# System_Mailbox_L4_CFGInterconnect register map
Vendor: Texas Instruments
Peripheral module from a debugger description file (folder omap4430).
Registers are 32-bit, read-write, reset 0x0 unless marked. A register's access mark holds for its fields unless they carry their own. Offsets are as the file gives them; lines under a group give offsets from that group; [hi:lo] are bit positions; {n}, {i} and the like mark numbered series; 'fields as' and 'values as' point back to an identical list; <NAME> marks a mode.

## System_Mailbox_L4_CFGInterconnect
0x00 MAILBOX_REVISION ro reset not defined — This register contains the IP revision code
  [31:0] REVISION — IP Revision
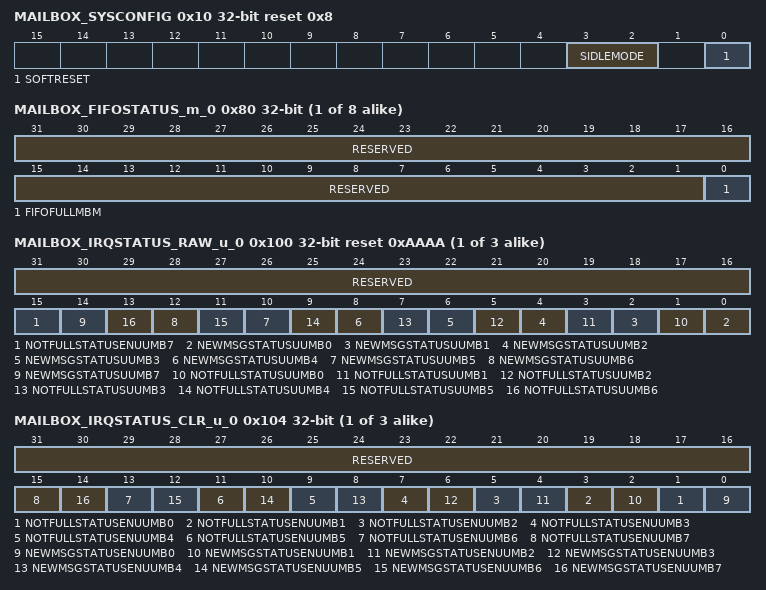
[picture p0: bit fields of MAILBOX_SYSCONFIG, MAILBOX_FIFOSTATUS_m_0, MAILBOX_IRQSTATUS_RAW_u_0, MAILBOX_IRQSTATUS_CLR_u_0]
0x10 MAILBOX_SYSCONFIG reset 0x8 — This register controls the various parameters of the communication interface
  [3:2] SIDLEMODE — Idle Mode
    0=Force-idle. An idle request is acknowledged unconditionally; 1=No-idle. An idle request is never acknowledged; 2=Smart-idle. Acknowledgement to an idle request is given based on the internal activity of the module based on the internal activity of the module; 3=reserved do not use
  [0] SOFTRESET
    0=SOFTRESET_0_r (Soft/Hard reset done); 0=SOFTRESET_0_w (No action); 1=SOFTRESET_1_r (Reset is ongoing); 1=SOFTRESET_1_w (Start the soft reset sequence)
{0x40+4i} MAILBOX_MESSAGE_m_{i} (i=0..7) — The message register stores the next to be read message of the mailbox. Reads remove the message from the FIFO queue.
  [31:0] MESSAGEVALUEMBM — Message in Mailbox
{0x80+4i} MAILBOX_FIFOSTATUS_m_{i} ro (i=0..7) — The FIFO status register has the status related to the mailbox internal FIFO
  [31:1] RESERVED — Reads returns 0
  [0] FIFOFULLMBM — Full flag for Mailbox
    0=FIFOFULLMBM_0_r (Mailbox FIFO is not full); 1=FIFOFULLMBM_1_r (Mailbox FIFO is full)
{0xC0+4i} MAILBOX_MSGSTATUS_m_{i} ro (i=0..7) — The message status register has the status of the messages in the mailbox.
  [2:0] NBOFMSGMBM — Number of unread messages in MailboxNote: Limited to four messages per mailbox.
{0x100+0x10*i} MAILBOX_IRQSTATUS_RAW_u_{i} reset 0xAAAA (i=0..2) — The interrupt status register has the raw status for each event that may be responsible for the generation of an interrupt to the corresponding user - write 1 to a given bit sets this bit. This register is mainly used for debug purpose.
  [31:16] RESERVED — Write 0's for future compatibility. Read returns 0.
  [15] NOTFULLSTATUSENUUMB7 — NotFull Status bit for User u, Mailbox 7
    0=NOTFULLSTATUSENUUMB7_0_r (No event pending (message queue full)); 0=NOTFULLSTATUSENUUMB7_0_w (No action); 1=NOTFULLSTATUSENUUMB7_1_r (Event pending (message queue not full)); 1=NOTFULLSTATUSENUUMB7_1_w (Set the event (for debug))
  [2n] NEWMSGSTATUSUUMB{n} (n=0..7) — NewMessage Status bit for User u, Mailbox {n}
    0=NEWMSGSTATUSUUMB{n}_0_r (No event (message) pending); 0=NEWMSGSTATUSUUMB{n}_0_w (No action); 1=NEWMSGSTATUSUUMB{n}_1_r (Event (message) pending); 1=NEWMSGSTATUSUUMB{n}_1_w (Set the event (for debug))
  [2n+1] NOTFULLSTATUSUUMB{n} (n=0..6) — NotFull Status bit for User u, Mailbox {n}
    0=NOTFULLSTATUSUUMB{n}_0_r (No event pending (message queue full)); 0=NOTFULLSTATUSUUMB{n}_0_w (No action); 1=NOTFULLSTATUSUUMB{n}_1_r (Event pending (message queue not full)); 1=NOTFULLSTATUSUUMB{n}_1_w (Set the event (for debug))
{0x104+0x10*i} MAILBOX_IRQSTATUS_CLR_u_{i} (i=0..2) — The interrupt status register has the status combined with irq-enable for each event that may be responsible for the generation of an interrupt to the corresponding user - write 1 to a given bit resets this bit
  [31:16] RESERVED — Write 0's for future compatibility. Read returns 0.
  [2n+1] NOTFULLSTATUSENUUMB{n} (n=0..7) — NotFull Status bit for User u, Mailbox {n}
    0=NOTFULLSTATUSENUUMB{n}_0_r (No event pending (message queue full)); 0=NOTFULLSTATUSENUUMB{n}_0_w (No action); 1=NOTFULLSTATUSENUUMB{n}_1_r (Event pending (message queue not full)); 1=NOTFULLSTATUSENUUMB{n}_1_w (Clear pending event, if any)
  [2n] NEWMSGSTATUSENUUMB{n} (n=0..7) — NewMessage Status bit for User u, Mailbox {n}
    0=NEWMSGSTATUSENUUMB{n}_0_r (No event (message) pending); 0=NEWMSGSTATUSENUUMB{n}_0_w (No action); 1=NEWMSGSTATUSENUUMB{n}_1_r (Event (message) pending); 1=NEWMSGSTATUSENUUMB{n}_1_w (Clear pending event, if any)
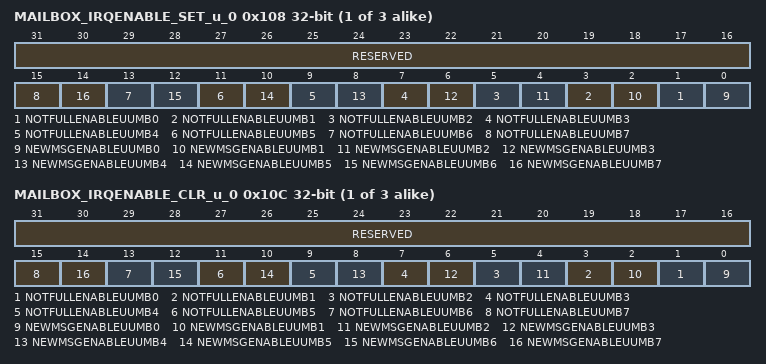
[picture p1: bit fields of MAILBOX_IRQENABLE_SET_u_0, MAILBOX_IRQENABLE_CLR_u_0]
{0x108+0x10*i} MAILBOX_IRQENABLE_SET_u_{i} (i=0..2) — The interrupt enable register enables to unmask the module internal source of interrupt to the corresponding user. This register is write 1 to set.
  [31:16] RESERVED — Write 0's for future compatibility. Read returns 0.
  [2n+1] NOTFULLENABLEUUMB{n} (n=0..7) — NotFull Enable bit for User u, Mailbox {n}
    0=NOTFULLENABLEUUMB{n}_0_r (Interupt disabled); 0=NOTFULLENABLEUUMB{n}_0_w (No action); 1=NOTFULLENABLEUUMB{n}_1_r (Interrupt enabled); 1=NOTFULLENABLEUUMB{n}_1_w (Enable interrupt)
  [2n] NEWMSGENABLEUUMB{n} (n=0..7) — NewMessage Enable bit for User u, Mailbox {n}
    0=NEWMSGENABLEUUMB{n}_0_r (Interupt disabled); 0=NEWMSGENABLEUUMB{n}_0_w (No action); 1=NEWMSGENABLEUUMB{n}_1_r (Interrupt enabled); 1=NEWMSGENABLEUUMB{n}_1_w (Enable interrupt)
{0x10C+0x10*i} MAILBOX_IRQENABLE_CLR_u_{i} (i=0..2) — The interrupt enable register enables to mask the module internal source of interrupt to the corresponding user. This register is write 1 to clear.
  [31:16] RESERVED — Write 0's for future compatibility. Read returns 0.
  [2n+1] NOTFULLENABLEUUMB{n} (n=0..7) — NotFull Enable bit for User u, Mailbox {n}
    0=NOTFULLENABLEUUMB{n}_0_r (Interupt disabled); 0=NOTFULLENABLEUUMB{n}_0_w (No action); 1=NOTFULLENABLEUUMB{n}_1_r (Interrupt enabled); 1=NOTFULLENABLEUUMB{n}_1_w (Disable interrupt)
  [2n] NEWMSGENABLEUUMB{n} (n=0..7) — NewMessage Enable bit for User u, Mailbox {n}
    0=NEWMSGENABLEUUMB{n}_0_r (Interupt disabled); 0=NEWMSGENABLEUUMB{n}_0_w (No action); 1=NEWMSGENABLEUUMB{n}_1_r (Interrupt enabled); 1=NEWMSGENABLEUUMB{n}_1_w (Disable interrupt)
